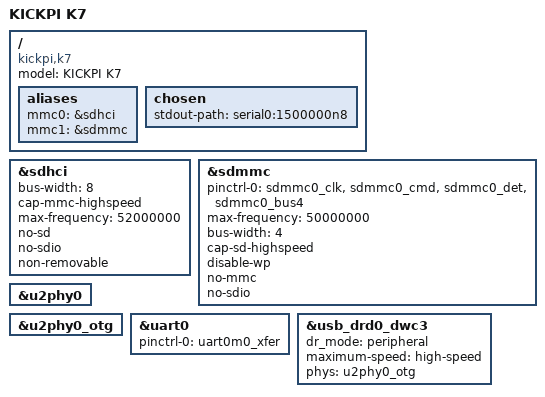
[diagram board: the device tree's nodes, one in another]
// SPDX-License-Identifier: (GPL-2.0+ OR MIT)
/*
 * KICKPI K7 Linux serial/MMC bring-up.
 * Board overrides for the Rockchip BSP RK3576 SoC device tree.
 * K7 topology cross-checked against the vendor rk3576-kickpi-k7.dts.
 * Keep boot firmware power rails; voltage switching/HS200 require board validation.
 *
 * 修改本文件前，请先对读这些出处：
 *
 * 参考模板   同 SoC EVB：arch/arm64/boot/dts/rockchip/rk3576-evb*.dts，
 *            板级结构与 EVB 一致，外设差异以 KICKPI 板卡 wiki/原理图为准。
 * 属性含义   Documentation/devicetree/bindings/（YAML），例：
 *            bus-width/max-frequency/disable-wp 见 mmc/rockchip-dw-mshc.yaml。
 * 引脚复用   rk3576-pinctrl.dtsi + 芯片 TRM 的 IOMUX 表。
 * 芯片手册   Rockchip 官网 TRM + opensource.rock-chips.com SDK 文档。
 * 存储标准   JEDEC（eMMC）/ SD Association 规范，bus-width、max-frequency 的依据。
 *
 * U-Boot 最小适配原则：本树只保留启动链外设（串口/存储/USB），
 * 内核才用的显示、网卡、音频等一律不写。
 */

/dts-v1/;

#include <dt-bindings/gpio/gpio.h>
#include "rk3576.dtsi"

/ {
	model = "KICKPI K7";
	compatible = "kickpi,k7", "rockchip,rk3576";

	aliases {
		mmc0 = &sdhci;
		mmc1 = &sdmmc;
	};

	chosen {
		stdout-path = "serial0:1500000n8";
	};
};

&sdhci {
	bus-width = <8>;
	cap-mmc-highspeed;
	max-frequency = <52000000>;
	no-sd;
	no-sdio;
	non-removable;
	status = "okay";
};

&sdmmc {
	/* Vendor K7 routes CLK/CMD/CD/DATA; do not inherit generic PWREN. */
	pinctrl-0 = <&sdmmc0_clk &sdmmc0_cmd &sdmmc0_det &sdmmc0_bus4>;
	max-frequency = <50000000>;
	bus-width = <4>;
	cap-sd-highspeed;
	disable-wp;
	no-mmc;
	no-sdio;
	status = "okay";
};

&u2phy0 {
	status = "okay";
};

&u2phy0_otg {
	status = "okay";
};

&uart0 {
	pinctrl-0 = <&uart0m0_xfer>;
	status = "okay";
};

&usb_drd0_dwc3 {
	dr_mode = "peripheral";
	maximum-speed = "high-speed";
	phys = <&u2phy0_otg>;
	phy-names = "usb2-phy";
	status = "okay";
};
